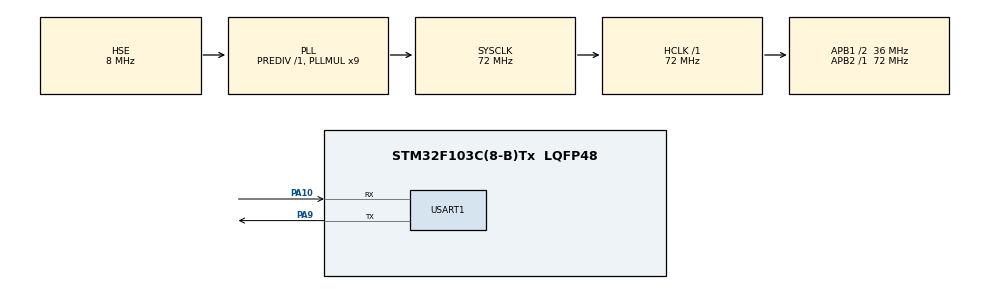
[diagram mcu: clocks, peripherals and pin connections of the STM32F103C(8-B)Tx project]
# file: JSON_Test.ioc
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Mcu.Family=STM32F1
Mcu.Name=STM32F103C(8-B)Tx
Mcu.Package=LQFP48
NVIC.PriorityGroup=NVIC_PRIORITYGROUP_4
PA10.Mode=Asynchronous
PA10.Signal=USART1_RX
PA13.Mode=Serial_Wire
PA13.Signal=SYS_JTMS-SWDIO
PA14.Mode=Serial_Wire
PA14.Signal=SYS_JTCK-SWCLK
PA9.Mode=Asynchronous
PA9.Signal=USART1_TX
PD0-OSC_IN.Mode=HSE-External-Oscillator
PD0-OSC_IN.Signal=RCC_OSC_IN
PD1-OSC_OUT.Mode=HSE-External-Oscillator
PD1-OSC_OUT.Signal=RCC_OSC_OUT
ProjectManager.HeapSize=0x1000
ProjectManager.StackSize=0x1000
ProjectManager.TargetToolchain=MDK-ARM V5.32
RCC.AHBFreq_Value=72000000
RCC.APB1CLKDivider=RCC_HCLK_DIV2
RCC.APB1Freq_Value=36000000
RCC.APB1TimFreq_Value=72000000
RCC.APB2Freq_Value=72000000
RCC.APB2TimFreq_Value=72000000
RCC.HCLKFreq_Value=72000000
RCC.PLLMUL=RCC_PLL_MUL9
RCC.PLLSourceVirtual=RCC_PLLSOURCE_HSE
RCC.SYSCLKFreq_VALUE=72000000
RCC.SYSCLKSource=RCC_SYSCLKSOURCE_PLLCLK
RCC.USBFreq_Value=72000000
USART1.VirtualMode=VM_ASYNC
board=custom

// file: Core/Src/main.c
/* USER CODE BEGIN Header */
/**
  ******************************************************************************
  * @file           : main.c
  * @brief          : Main program body
  ******************************************************************************
  * @attention
  *
  * Copyright (c) 2023 STMicroelectronics.
  * All rights reserved.
  *
  * This software is licensed under terms that can be found in the LICENSE file
  * in the root directory of this software component.
  * If no LICENSE file comes with this software, it is provided AS-IS.
  *
  ******************************************************************************
  */
/* USER CODE END Header */
#include "main.h"
#include "usart.h"
#include "gpio.h"

/* USER CODE BEGIN Includes */
#include "jansson.h"
//#include "retarget.h"
/* USER CODE END Includes */

void SystemClock_Config(void);

/* USER CODE BEGIN 0 */
void _Add_array_to_json(json_t *obj,const char* name,const int *marr,size_t dim1,size_t dim2);
/* USER CODE END 0 */

int main(void)
{
  /* USER CODE BEGIN 1 */
	json_t *root;
	json_t *jdata;

	json_t *Test_obj;
	json_t *Array_obj;
	json_t *item1_obj;
	json_t *item2_obj;

	json_t *_Test_obj;
	json_t *_Array_obj;
	json_t *_item1_obj;
	json_t *_item2_obj;

	char *out;
	char *s;

	int array_1[2][3] = {{1,2,3},{4,5,6}};
	int array_2[4][4] = {{1,2,3,4}, {5,6,7,8}, {9,10,11,12}, {13,14,15,16}};
	json_error_t error;
  /* USER CODE END 1 */

  /* MCU Configuration--------------------------------------------------------*/

  /* Reset of all peripherals, Initializes the Flash interface and the Systick. */
  HAL_Init();

  /* Configure the system clock */
  SystemClock_Config();

  /* Initialize all configured peripherals */
  MX_GPIO_Init();
  MX_USART1_UART_Init();
  /* USER CODE BEGIN 2 */
	root = json_pack("{}");

	out = json_dumps(root, JSON_ENCODE_ANY);
	printf("out:%s\r\n",out);
	free(root);
	free(out);

	root = json_pack("{sisi}", "foo", 42 ,"bar", 7);
	out = json_dumps(root, JSON_ENCODE_ANY);
	printf("out:%s\r\n",out);
	free(root);
	free(out);

	root = json_pack("{s:i,s:i}", "foo", 42 ,"bar", 7);
	out = json_dumps(root, JSON_ENCODE_ANY);
	printf("out:%s\r\n",out);
	free(root);
	free(out);

  root = json_pack("[[i,i],{s:b}]", 1, 42 ,"cool", 7);
	out = json_dumps(root, JSON_ENCODE_ANY);
	printf("out:%s\r\n",out);
	free(root);
	free(out);

	char buffer[4] = {'t','e','s','t'};
	root = json_pack("s#",buffer,4);
	out = json_dumps(root, JSON_ENCODE_ANY);
	printf("out:%s\r\n", out);
	free(root);
	free(out);

	root = json_pack("s++","foo","bar","baz");
	out = json_dumps(root, JSON_ENCODE_ANY);
	printf("out:%s\r\n", out);
	free(root);
	free(out);

	root = json_pack("{s:s*,s:o*,s:O*}","foo",NULL,"bar",NULL,"baz",NULL);
	out = json_dumps(root, JSON_ENCODE_ANY);
	printf("out:%s\r\n", out);
	free(root);
	free(out);

	root = json_pack("[s*,o*,O*]",NULL,NULL,NULL);
	out = json_dumps(root, JSON_ENCODE_ANY);
	printf("out:%s\r\n", out);
	free(root);
	free(out);

	jdata = json_object();
	_Add_array_to_json(jdata,"arr1",&array_1[0][0],2,3);
	_Add_array_to_json(jdata,"arr2",&array_2[0][0],4,4);
  s = json_dumps(jdata, 0);
	puts(s);
	free(s);

	json_decref(jdata);
	json_decref(jdata);

	Test_obj = json_object();
	item1_obj = json_object();
	item2_obj = json_object();

	json_object_set_new(Test_obj,"Title",json_string("Hello World"));
  json_object_set_new(Test_obj,"name",json_string("Test_obj"));

	json_object_set_new(Test_obj,"num_1",json_true());
  json_object_set_new(Test_obj,"num_2",json_false());

	json_object_set_new(Test_obj,"num_3",json_integer(1));
  json_object_set_new(Test_obj,"num_4",json_real(1.55));

	json_object_set_new(item1_obj,"item1",json_string("item1_obj"));
  json_object_set_new(item2_obj,"item1",json_string("item2_obj"));

	Array_obj = json_array();

	json_array_append_new(Array_obj,item1_obj);
	json_array_append_new(Array_obj,item2_obj);

	json_object_set_new(Test_obj,"Children_1",Array_obj);

	out = json_dumps(Test_obj, JSON_ENCODE_ANY);
	printf("out:%s\r\n", out);

	json_decref(Test_obj);

	_Test_obj = json_loads(out , 0, &error);
	_Array_obj = json_object_get(_Test_obj,"Children_1");
	int size = json_array_size(_Array_obj);

	_item1_obj = json_object_get(_Test_obj,"num1");
	printf("Test num1 type is : %d, val: %d,%f\r\n", json_typeof(_item1_obj),json_boolean_value(_item1_obj),json_number_value(_item1_obj));

	free(out);
	json_decref(_Test_obj);
	/* USER CODE END 2 */

  /* Infinite loop */
  while (1)
  {

  }
}

void SystemClock_Config(void)
{
  RCC_OscInitTypeDef RCC_OscInitStruct = {0};
  RCC_ClkInitTypeDef RCC_ClkInitStruct = {0};

  /** Initializes the RCC Oscillators according to the specified parameters
  * in the RCC_OscInitTypeDef structure.
  */
  RCC_OscInitStruct.OscillatorType = RCC_OSCILLATORTYPE_HSE;
  RCC_OscInitStruct.HSEState = RCC_HSE_ON;
  RCC_OscInitStruct.HSEPredivValue = RCC_HSE_PREDIV_DIV1;
  RCC_OscInitStruct.HSIState = RCC_HSI_ON;
  RCC_OscInitStruct.PLL.PLLState = RCC_PLL_ON;
  RCC_OscInitStruct.PLL.PLLSource = RCC_PLLSOURCE_HSE;
  RCC_OscInitStruct.PLL.PLLMUL = RCC_PLL_MUL9;
  if (HAL_RCC_OscConfig(&RCC_OscInitStruct) != HAL_OK)
  {
    Error_Handler();
  }

  /** Initializes the CPU, AHB and APB buses clocks
  */
  RCC_ClkInitStruct.ClockType = RCC_CLOCKTYPE_HCLK|RCC_CLOCKTYPE_SYSCLK
                              |RCC_CLOCKTYPE_PCLK1|RCC_CLOCKTYPE_PCLK2;
  RCC_ClkInitStruct.SYSCLKSource = RCC_SYSCLKSOURCE_PLLCLK;
  RCC_ClkInitStruct.AHBCLKDivider = RCC_SYSCLK_DIV1;
  RCC_ClkInitStruct.APB1CLKDivider = RCC_HCLK_DIV2;
  RCC_ClkInitStruct.APB2CLKDivider = RCC_HCLK_DIV1;

  if (HAL_RCC_ClockConfig(&RCC_ClkInitStruct, FLASH_LATENCY_2) != HAL_OK)
  {
    Error_Handler();
  }
}

/* USER CODE BEGIN 4 */
void _Add_array_to_json(json_t *obj,const char* name,const int *marr,size_t dim1,size_t dim2)
{
	size_t i,j;
	json_t* j_arr1 = json_array();
	for(i = 0;i < dim1; i++)
	{
		json_t* j_arr2 = json_array();
		for(j = 0;j < dim2; j++)
		{
			int val = marr[i*dim2 + j];
			json_t* jval = json_integer(val);
			json_array_append_new(j_arr2,jval);
		}
		json_array_append_new(j_arr1,j_arr2);
	}
	json_object_set_new(obj, name, j_arr1);
	return;
}

int fputc(int data,FILE *file)
{
	uint8_t ch = data;
	HAL_UART_Transmit(&huart1,&ch,1,100);
	return 1;
}
/* USER CODE END 4 */

void Error_Handler(void)
{
  __disable_irq();
  while (1)
  {
  }
}
